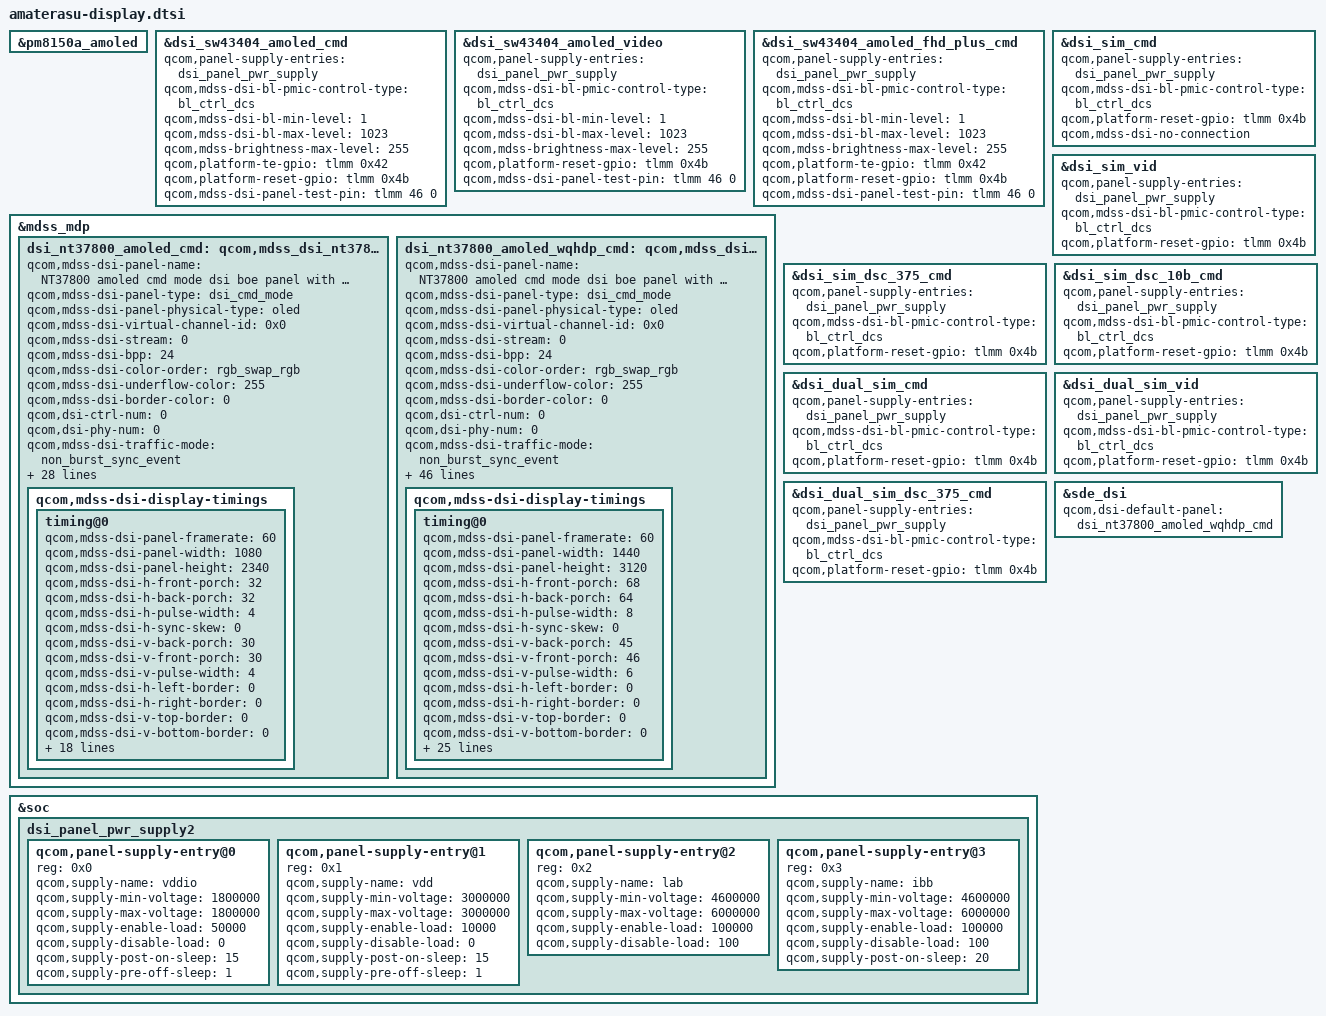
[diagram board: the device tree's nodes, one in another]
/*
 * FCNT arrows 5G (F-51A) - Display: NT37800 AMOLED panels (WQHD+/FHD+, DSC cmd mode), panel supplies and DSI.
 *
 * Reconstructed from the FCNT stock dtbo (kona FFRD REV7 SKU3); FFRD is
 * derived from the CLO kona QRD board files.
 */

&pm8150a_amoled {
	status = "ok";
};

&dsi_sw43404_amoled_cmd {
	qcom,panel-supply-entries = <&dsi_panel_pwr_supply>;
	qcom,mdss-dsi-bl-pmic-control-type = "bl_ctrl_dcs";
	qcom,mdss-dsi-bl-min-level = <1>;
	qcom,mdss-dsi-bl-max-level = <1023>;
	qcom,mdss-brightness-max-level = <255>;
	qcom,platform-te-gpio = <&tlmm 0x42 0x0>;
	qcom,platform-reset-gpio = <&tlmm 0x4b 0x0>;
	qcom,mdss-dsi-panel-test-pin = <&tlmm 46 0>;
};

&dsi_sw43404_amoled_video {
	qcom,panel-supply-entries = <&dsi_panel_pwr_supply>;
	qcom,mdss-dsi-bl-pmic-control-type = "bl_ctrl_dcs";
	qcom,mdss-dsi-bl-min-level = <1>;
	qcom,mdss-dsi-bl-max-level = <1023>;
	qcom,mdss-brightness-max-level = <255>;
	qcom,platform-reset-gpio = <&tlmm 0x4b 0x0>;
	qcom,mdss-dsi-panel-test-pin = <&tlmm 46 0>;
};

&dsi_sw43404_amoled_fhd_plus_cmd {
	qcom,panel-supply-entries = <&dsi_panel_pwr_supply>;
	qcom,mdss-dsi-bl-pmic-control-type = "bl_ctrl_dcs";
	qcom,mdss-dsi-bl-min-level = <1>;
	qcom,mdss-dsi-bl-max-level = <1023>;
	qcom,mdss-brightness-max-level = <255>;
	qcom,platform-te-gpio = <&tlmm 0x42 0x0>;
	qcom,platform-reset-gpio = <&tlmm 0x4b 0x0>;
	qcom,mdss-dsi-panel-test-pin = <&tlmm 46 0>;
};

&mdss_mdp {
	dsi_nt37800_amoled_cmd: qcom,mdss_dsi_nt37800_amoled_fhdp_cmd {
		qcom,mdss-dsi-panel-name = "NT37800 amoled cmd mode dsi boe panel with DSC";
		qcom,mdss-dsi-panel-type = "dsi_cmd_mode";
		qcom,mdss-dsi-panel-physical-type = "oled";
		qcom,mdss-dsi-virtual-channel-id = <0x0>;
		qcom,mdss-dsi-stream = <0>;
		qcom,mdss-dsi-bpp = <24>;
		qcom,mdss-dsi-color-order = "rgb_swap_rgb";
		qcom,mdss-dsi-underflow-color = <255>;
		qcom,mdss-dsi-border-color = <0>;
		qcom,dsi-ctrl-num = <0>;
		qcom,dsi-phy-num = <0>;
		qcom,mdss-dsi-traffic-mode = "non_burst_sync_event";
		qcom,mdss-dsi-lane-map = "lane_map_0123";
		qcom,mdss-dsi-bllp-eof-power-mode;
		qcom,mdss-dsi-bllp-power-mode;
		qcom,mdss-dsi-lane-0-state;
		qcom,mdss-dsi-lane-1-state;
		qcom,mdss-dsi-lane-2-state;
		qcom,mdss-dsi-lane-3-state;
		qcom,mdss-dsi-dma-trigger = "trigger_sw";
		qcom,mdss-dsi-mdp-trigger = "none";
		qcom,mdss-dsi-reset-sequence = <1 15 0 1 1 10>;
		qcom,mdss-dsi-te-pin-select = <1>;
		qcom,mdss-dsi-wr-mem-start = <44>;
		qcom,mdss-dsi-wr-mem-continue = <60>;
		qcom,mdss-dsi-te-dcs-command = <0x1>;
		qcom,mdss-dsi-te-check-enable;
		qcom,mdss-dsi-te-using-te-pin;
		qcom,mdss-dsi-lp11-init;
		qcom,dsi-select-clocks = "mux_byte_clk0", "mux_pixel_clk0";
		qcom,panel-supply-entries = <&dsi_panel_pwr_supply2>;
		qcom,mdss-dsi-bl-pmic-control-type = "bl_ctrl_dcs";
		qcom,mdss-dsi-bl-min-level = <1>;
		qcom,mdss-dsi-bl-max-level = <4095>;
		qcom,mdss-brightness-max-level = <255>;
		qcom,platform-te-gpio = <&tlmm 0x42 0x0>;
		qcom,platform-reset-gpio = <&tlmm 0x4b 0x0>;

		qcom,mdss-dsi-display-timings {
			timing@0 {
				qcom,mdss-dsi-panel-framerate = <60>;
				qcom,mdss-dsi-panel-width = <1080>;
				qcom,mdss-dsi-panel-height = <2340>;
				qcom,mdss-dsi-h-front-porch = <32>;
				qcom,mdss-dsi-h-back-porch = <32>;
				qcom,mdss-dsi-h-pulse-width = <4>;
				qcom,mdss-dsi-h-sync-skew = <0>;
				qcom,mdss-dsi-v-back-porch = <30>;
				qcom,mdss-dsi-v-front-porch = <30>;
				qcom,mdss-dsi-v-pulse-width = <4>;
				qcom,mdss-dsi-h-left-border = <0>;
				qcom,mdss-dsi-h-right-border = <0>;
				qcom,mdss-dsi-v-top-border = <0>;
				qcom,mdss-dsi-v-bottom-border = <0>;
				qcom,mdss-dsi-panel-jitter = <4 1>;
				qcom,mdss-dsi-on-command = <0x39010000 0x6f0 0x55aa5208 0x390100 0x25 0xb3000100 0x32003200 0x64006400 0xc800c801 0x2c012c01 0x90019003 0x48034804 0xb004b006 0x4006400f 0xff390100 0x1e 0xb4999999 0x88887755 0x3300000d 0xd0d0d0d 0xdc6c650 0x50dada8c 0x8cf4f438 0x38383901 0x0 0x26f0139 0x1000000 0x2b500 0x39010000 0x26f 0x5390100 0x2 0xb57f3901 0x0 0x6f055aa 0x52080039 0x1000000 0x26f06 0x39010000 0x4b5 0x48230039 0x1000000 0x26f0b 0x39010000 0x4b5 0x48230039 0x1000000 0x16b200 0x60202000 0x8080000 0x20000000 0x20000000 0x0 0x39010000 0x26f 0x24390100 0x9 0xb302a006 0x750f870f 0xff390100 0x2 0x6f243901 0x0 0xbb403b4 0x3b403b4 0x3b403b4 0x39010000 0x26f 0xb390100 0x2 0xb2003901 0x0 0x3b91000 0x39010000 0x9ba 0x1ac0010 0x208001 0x39010000 0x26f 0x8390100 0x9 0xba01ac00 0x10002000 0x20390100 0x2 0x6f103901 0x0 0xfba01ac 0x100020 0x1ac0010 0x200000 0x39010000 0x26f 0x1e390100 0x5 0xba110101 0x1390100 0x9 0xbb01ac00 0x10002000 0x41390100 0x4 0xbde100e1 0x39010000 0x6be 0xe10111f 0x1f390100 0x3 0xc0767339 0x1000000 0x26f02 0x39010000 0x2c0 0x390100 0x2 0x6f0e3901 0x0 0x2ba3839 0x1000000 0x26f03 0x39010000 0x4c0 0x39 0x1000000 0x3c100 0x62390100 0x2 0xc2013901 0x0 0x7c30000 0x0 0x39010000 0x3c5 0x5003901 0x0 0x5c63f00 0x3901 0x0 0x2c80d39 0x1000000 0x2c984 0x39010000 0x2ca 0x33390100 0x2 0xcb883901 0x0 0x2df0039 0x1000000 0x26f22 0x39010000 0x3df 0x803901 0x0 0x6f055aa 0x52080139 0x1000000 0x3b000 0x390100 0x3 0xb3050139 0x1000000 0x7b714 0x14141414 0x14390100 0x3 0xb1000039 0x1000000 0x3b405 0x1390100 0x5 0xb83d3d3d 0x3d390100 0x7 0xb500d700 0xd700d739 0x1000000 0x7b600 0x78007800 0x78390100 0x9 0xc200d700 0x7800d700 0x78390100 0x9 0xb91e1a1e 0x1a1e1a1e 0x1a390100 0x5 0xba101410 0x14390100 0x3 0xbb1e1e39 0x1000000 0x3cd05 0x82390100 0x2 0xc7013901 0x0 0x26f0139 0x1000000 0x4ce28 0x1003901 0x0 0x5cf0d02 0x13073901 0x0 0x2bc1139 0x1000000 0x11bd96 0x690000 0x960069bb 0x4444bbee 0x1111ee39 0x1000000 0x2c102 0x39010000 0x9c2 0x19009100 0x19009100 0x39010000 0x3c0 0x3901 0x0 0x6f055aa 0x52080339 0x1000000 0x6b000 0x2 0x39010000 0xbb2 0xc 0x1000000 0xc013901 0x0 0xbb30000 0xd2100 0xd21 0x39010000 0x7b4 0x0 0x3901 0x0 0x16b60300 0x0 0xd00 0x0 0xd000000 0x39 0x1000000 0x8bb22 0x181600 0x18163901 0x0 0x8bc2210 0x1e4c001e 0x4c390100 0x8 0xbd110009 0x60000960 0x39010000 0x4c3 0xa39 0x1000000 0x6f055 0xaa520805 0x39010000 0x4b0 0x7230039 0x1000000 0x3b388 0x80390100 0x3 0xb5040539 0x1000000 0x3b686 0x85390100 0x5 0xb7040000 0x5390100 0x5 0xb8040000 0x5390100 0x5 0xb9040000 0x5390100 0x3 0xc7070139 0x1000000 0x2ca33 0x39010000 0x4cb 0x33333339 0x1000000 0x2d822 0x39010000 0x2d9 0x1390100 0x4 0xd0000020 0x39010000 0x4d1 0x31039 0x1000000 0x4d200 0x8103901 0x0 0x5e00200 0x3901 0x0 0x5e10200 0x33901 0x0 0x5e20099 0x28003901 0x0 0x3ec0111 0x39010000 0x6f0 0x55aa5208 0x6390100 0x6 0xb0041011 0x34003901 0x0 0x6b1000e 0xe0f0f39 0x1000000 0x6b20c 0xc0d0d34 0x39010000 0x6b3 0x34343434 0x34390100 0x5 0xb4141415 0x15390100 0x6 0xb6041011 0x34003901 0x0 0x6b7000e 0xe0f0f39 0x1000000 0x6b80c 0xc0d0d34 0x39010000 0x6b9 0x34343434 0x34390100 0x5 0xba141415 0x15390100 0x2 0xd0013901 0x0 0x6f055aa 0x52080739 0x1000000 0x7b0a4 0x40706000 0x390100 0x3 0xb7809039 0x1000000 0x26f43 0x39010000 0x4b7 0x80708039 0x1000000 0x26f46 0x39010000 0x4b7 0x80708039 0x1000000 0x18b10c 0x1c001c0c 0x0 0x0 0x0 0x0 0x3901 0x0 0xb5b22222 0x22222222 0x22222222 0x22222222 0x22222222 0x0 0x0 0x222222 0x22222222 0x22222222 0x22222222 0x22222200 0x0 0x0 0x3a3a3a3a 0x3a3a3a3a 0x3a050505 0x5050505 0x5053a3a 0x3a3a3a3a 0x3a3a3a05 0x5050505 0x5050505 0x0 0x0 0x0 0x0 0x3a3a 0x3a3a3a3a 0x3a3a3a05 0x5050505 0x5050505 0x3a3a3a3a 0x3a3a3a3a 0x3a050505 0x5050505 0x5050000 0x0 0x0 0x0 0x0 0x0 0x0 0x0 0x0 0x3901 0x0 0x5bb30000 0x0 0x0 0x0 0x0 0x0 0x0 0x0 0x0 0x0 0x0 0x0 0x0 0x0 0x0 0x0 0x0 0x0 0x0 0x0 0x0 0x0 0x0 0x39010000 0x1bb4 0xc0000000 0x0 0x0 0x8068 0x80806080 0x80608080 0xa0803901 0x0 0x49b50000 0x0 0x0 0x0 0x0 0x0 0x4000000 0x0 0x0 0x0 0x0 0x0 0x0 0x0 0x0 0x0 0x0 0x0 0x3901 0x0 0x25b60000 0x0 0x0 0x0 0x0 0x0 0xe000 0xe0000000 0xe000e000 0x3901 0x0 0x58b80000 0x0 0x0 0x0 0x0 0x20200 0x0 0x0 0x0 0x0 0x0 0x0 0x0 0x0 0x0 0x0 0x0 0x0 0x0 0x0 0x0 0x0 0x390100 0xc1 0xb9000000 0x0 0x0 0x0 0x0 0x0 0x0 0x0 0x0 0x0 0x0 0x0 0x0 0x0 0x0 0x0 0x0 0x0 0x0 0x0 0x0 0x0 0x0 0x0 0x0 0x0 0x0 0x0 0x0 0x0 0x0 0x0 0x0 0x0 0x0 0x0 0x0 0x0 0x0 0x0 0x0 0x0 0x0 0x0 0x0 0x0 0x0 0x0 0x390100 0x20 0xba000000 0x0 0x0 0x0 0x0 0x0 0x0 0x0 0x39010000 0x88bb 0x0 0x0 0x0 0x0 0x0 0x0 0x0 0x0 0x0 0x0 0x0 0x0 0x0 0x0 0x0 0x0 0x0 0x0 0x0 0x0 0x0 0x0 0x0 0x0 0x0 0x0 0x0 0x0 0x0 0x0 0x0 0x0 0x0 0x39 0x1000000 0x14bc00 0x0 0x0 0x0 0x0 0x3901 0x0 0xdbd0000 0x0 0x0 0x3901 0x0 0x6f055aa 0x52080739 0x1000000 0x2c011 0x39010000 0x27c1 0x603c0349 0xf7d80510 0x3ffd9664 0x3ffb843c 0x7163 0xa41d0020 0x7e1d 0x0 0x1f1df7ff 0xffff3901 0x0 0x27c2483c 0x441f90a 0x2d93ffb 0x69c23ffd 0x9ea60000 0x7e398161 0x1e00 0x1f7ff7ff 0xfff7ffff 0xf7ffffff 0x39010000 0x27c3 0x6c000441 0x6f602d9 0x3ff8c68c 0x38e8 0x0 0x618000 0xa4901f05 0x90000690 0x1f23f7ff 0xffff3901 0x0 0x27c44400 0x3490828 0x5103ffc 0xa9dc0003 0x56240000 0x1d 0x90200690 0x7e23f7ff 0xfff7ffff 0xf7ffffff 0x39010000 0x27c5 0x623c0349 0xf7d80510 0xec88 0x654d4 0x7fff37c2 0x6c1d93b9 0x6941723 0x94180694 0x3723f7ff 0xffff3901 0x0 0x27c64a3c 0x441f802 0x3c10006 0xf6be0000 0xf7c27fff 0x1826fd61 0x8418a494 0x3705f7ff 0xfff7ffff 0xf7ffffff 0x39010000 0x27c7 0x660004c9 0x87a03c1 0x3df08 0x3ffc20f8 0x0 0x418 0x1e04377f 0x4180004 0x371df7ff 0xffff3901 0x0 0x27c84600 0x3490828 0x5100000 0x3ff8 0x858c0000 0x1d 0x3b90004 0x171df7ff 0xfff7ffff 0xf7ffffff 0x39010000 0x27c9 0x0 0x0 0x0 0x0 0x0 0xf7ff 0xfff7ffff 0xf7fffff7 0xfffff7ff 0xffff3901 0x0 0x27ca0000 0x0 0x0 0x0 0x0 0x0 0xf7fffff7 0xfffff7ff 0xfff7ffff 0xf7ffffff 0x39010000 0x27cb 0x0 0x0 0x0 0x0 0x0 0xf7ff 0xfff7ffff 0xf7fffff7 0xfffff7ff 0xffff3901 0x0 0x27cc0000 0x0 0x0 0x0 0x0 0x0 0xf7fffff7 0xfffff7ff 0xfff7ffff 0xf7ffffff 0x39010000 0x27cd 0x20000000 0x0 0x0 0x0 0x0 0x179 0x19c1a 0x19d0001 0xa015f7ff 0xffff3901 0x0 0x27ce0000 0x0 0x0 0x0 0x0 0x0 0x19d1601 0xe74ff7ff 0xfff7ffff 0xf7ffffff 0x39010000 0x27cf 0x20000000 0x0 0x0 0x0 0x0 0x250 0x16029a4f 0x2970002 0x9a15f7ff 0xffff3901 0x0 0x27d00000 0x0 0x0 0x0 0x0 0x0 0x29b0002 0xbe1a9000 0x6f7ffff 0xf7ffffff 0x39010000 0x5ff 0xaa55a581 0x39010000 0x26f 0x2c390100 0x2 0xfa003901 0x0 0x6f055aa 0x52000039 0x1000000 0x23500 0x39010000 0x53b 0x100004 0x39010000 0x253 0x20390100 0x5 0x5100ff0f 0xff390100 0x5 0x510fff0f 0xff390100 0x5 0x2a000004 0x37390100 0x5 0x2b000009 0x23390100 0x13 0x93892800 0x14020002 0xe01e800 0x7050e05 0x1610f039 0x1000000 0x29001 0x39010000 0x203 0x11390100 0x2 0x2c003901 0x0 0x22f0139 0x1000000 0x6f055 0xaa520800 0x39010000 0x26f 0xe390100 0x2 0xba383901 0x0 0x26f0339 0x1000000 0x4c080 0x3901 0x7800 0x2110005 0x1000000 0x22900>;
				qcom,mdss-dsi-off-command = [05 01 00 00 23 00 02 28 00 05 01 00 00 78 00 02 10 00];
				qcom,mdss-dsi-on-command-state = "dsi_lp_mode";
				qcom,mdss-dsi-off-command-state = "dsi_hs_mode";
				qcom,compression-mode = "dsc";
				qcom,mdss-dsc-slice-height = <20>;
				qcom,mdss-dsc-slice-width = <540>;
				qcom,mdss-dsc-slice-per-pkt = <2>;
				qcom,mdss-dsc-bit-per-component = <8>;
				qcom,mdss-dsc-bit-per-pixel = <8>;
				qcom,mdss-dsc-block-prediction-enable;
				qcom,mdss-dsi-panel-phy-timings = [00 0f 03 03 1e 1d 04 04 02 02 04 00 0f 13];
				qcom,display-topology = <2 2 1>;
				qcom,default-topology-index = <0>;
			};
		};
	};

	dsi_nt37800_amoled_wqhdp_cmd: qcom,mdss_dsi_nt37800_amoled_wqhdp_cmd {
		qcom,mdss-dsi-panel-name = "NT37800 amoled cmd mode dsi boe panel with DSC";
		qcom,mdss-dsi-panel-type = "dsi_cmd_mode";
		qcom,mdss-dsi-panel-physical-type = "oled";
		qcom,mdss-dsi-virtual-channel-id = <0x0>;
		qcom,mdss-dsi-stream = <0>;
		qcom,mdss-dsi-bpp = <24>;
		qcom,mdss-dsi-color-order = "rgb_swap_rgb";
		qcom,mdss-dsi-underflow-color = <255>;
		qcom,mdss-dsi-border-color = <0>;
		qcom,dsi-ctrl-num = <0>;
		qcom,dsi-phy-num = <0>;
		qcom,mdss-dsi-traffic-mode = "non_burst_sync_event";
		qcom,mdss-dsi-lane-map = "lane_map_0123";
		qcom,mdss-dsi-bllp-eof-power-mode;
		qcom,mdss-dsi-bllp-power-mode;
		qcom,mdss-dsi-lane-0-state;
		qcom,mdss-dsi-lane-1-state;
		qcom,mdss-dsi-lane-2-state;
		qcom,mdss-dsi-lane-3-state;
		qcom,mdss-dsi-dma-trigger = "trigger_sw";
		qcom,mdss-dsi-mdp-trigger = "none";
		qcom,mdss-dsi-reset-sequence = <1 15 0 1 1 10>;
		qcom,mdss-dsi-te-pin-select = <1>;
		qcom,mdss-dsi-wr-mem-start = <44>;
		qcom,mdss-dsi-wr-mem-continue = <60>;
		qcom,mdss-dsi-te-dcs-command = <0x1>;
		qcom,mdss-dsi-te-check-enable;
		qcom,mdss-dsi-te-using-te-pin;
		qcom,mdss-dsi-lp11-init;
		qcom,mdss-pan-physical-width-dimension = <71>;
		qcom,mdss-pan-physical-height-dimension = <154>;
		qcom,mdss-dsi-panel-hdr-enabled;
		qcom,mdss-dsi-panel-hdr-color-primaries = <14950 15750 33950 16000 13000 35200 7000 2600>;
		qcom,mdss-dsi-panel-peak-brightness = <4200000>;
		qcom,mdss-dsi-panel-blackness-level = <1>;
		qcom,esd-check-enabled;
		qcom,mdss-dsi-panel-status-check-mode = "reg_read";
		qcom,mdss-dsi-panel-status-command = <0x6010001 0x10a>;
		qcom,mdss-dsi-panel-status-command-state = "dsi_lp_mode";
		qcom,mdss-dsi-panel-status-value = <156>;
		qcom,mdss-dsi-panel-status-read-length = <1>;
		qcom,dsi-select-clocks = "mux_byte_clk0", "mux_pixel_clk0";
		qcom,panel-supply-entries = <&dsi_panel_pwr_supply2>;
		qcom,mdss-dsi-bl-pmic-control-type = "bl_ctrl_dcs";
		qcom,mdss-dsi-bl-min-level = <1>;
		qcom,mdss-dsi-bl-max-level = <2874>;
		qcom,mdss-dsi-bl-super-clear-level = <4095>;
		qcom,mdss-brightness-max-level = <255>;
		qcom,platform-te-gpio = <&tlmm 0x42 0x0>;
		qcom,platform-reset-gpio = <&tlmm 0x4b 0x0>;
		qcom,mdss-dsi-panel-test-pin = <&tlmm 46 0>;

		qcom,mdss-dsi-display-timings {
			timing@0 {
				qcom,mdss-dsi-panel-framerate = <60>;
				qcom,mdss-dsi-panel-width = <1440>;
				qcom,mdss-dsi-panel-height = <3120>;
				qcom,mdss-dsi-h-front-porch = <68>;
				qcom,mdss-dsi-h-back-porch = <64>;
				qcom,mdss-dsi-h-pulse-width = <8>;
				qcom,mdss-dsi-h-sync-skew = <0>;
				qcom,mdss-dsi-v-back-porch = <45>;
				qcom,mdss-dsi-v-front-porch = <46>;
				qcom,mdss-dsi-v-pulse-width = <6>;
				qcom,mdss-dsi-h-left-border = <0>;
				qcom,mdss-dsi-h-right-border = <0>;
				qcom,mdss-dsi-v-top-border = <0>;
				qcom,mdss-dsi-v-bottom-border = <0>;
				qcom,mdss-dsi-panel-jitter = <4 1>;
				qcom,mdss-dsi-on-command = [39 01 00 00 00 00 06 f0 55 aa 52 08 00 39 01 00 00 00 00 03 b5 84 00 39 01 00 00 00 00 02 6f 05 39 01 00 00 00 00 05 b5 7f 48 16 51 39 01 00 00 00 00 08 b7 aa aa aa aa 86 42 10 39 01 00 00 00 00 02 6f 0b 39 01 00 00 00 00 04 b5 48 29 00 39 01 00 00 00 00 06 f0 55 aa 52 08 00 39 01 00 00 00 00 04 c0 76 73 00 39 01 00 00 00 00 06 f0 55 aa 52 08 01 39 01 00 00 00 00 02 6f 05 39 01 00 00 00 00 03 d2 40 07 39 01 00 00 00 00 05 ff aa 55 a5 81 39 01 00 00 00 00 02 6f 0d 39 01 00 00 00 00 02 f3 cb 39 01 00 00 00 00 02 6f 2c 39 01 00 00 00 00 02 fa 00 39 01 00 00 00 00 05 ff aa 55 a5 80 39 01 00 00 00 00 02 6f 0a 39 01 00 00 00 00 02 fc 02 39 01 00 00 00 00 05 ff aa 55 a5 00 39 01 00 00 00 00 06 f0 55 aa 52 00 00 39 01 00 00 00 00 02 35 00 39 01 00 00 00 00 05 3b 00 08 00 08 39 01 00 00 00 00 02 53 20 39 01 00 00 00 00 05 51 00 00 0f ff 39 01 00 00 00 00 05 2a 00 00 05 9f 39 01 00 00 00 00 05 2b 00 00 0c 2f 39 01 00 00 00 00 13 93 89 28 00 14 02 00 02 68 02 2e 00 0a 05 0e 03 d1 10 f0 39 01 00 00 00 00 02 90 01 39 01 00 00 00 00 02 03 11 39 01 00 00 00 00 02 2c 00 39 01 00 00 78 00 02 11 00 05 01 00 00 00 00 02 29 00];
				qcom,mdss-dsi-off-command = [05 01 00 00 23 00 02 28 00 05 01 00 00 78 00 02 10 00];
				qcom,mdss-dsi-on-command-state = "dsi_lp_mode";
				qcom,mdss-dsi-off-command-state = "dsi_hs_mode";
				qcom,mdss-dsi-lp1-command = [05 01 00 00 00 00 02 39 00 39 01 00 00 00 00 02 65 01 39 01 00 00 00 00 02 2c 00];
				qcom,mdss-dsi-lp1-command-state = "dsi_lp_mode";
				qcom,mdss-dsi-nolp-command = [05 01 00 00 00 00 02 38 00 39 01 00 00 00 00 02 65 00 39 01 00 00 00 00 02 2c 00];
				qcom,mdss-dsi-nolp-command-state = "dsi_lp_mode";
				qcom,compression-mode = "dsc";
				qcom,mdss-dsc-slice-height = <20>;
				qcom,mdss-dsc-slice-width = <720>;
				qcom,mdss-dsc-slice-per-pkt = <2>;
				qcom,mdss-dsc-bit-per-component = <8>;
				qcom,mdss-dsc-bit-per-pixel = <8>;
				qcom,mdss-dsc-block-prediction-enable;
				qcom,mdss-dsi-panel-phy-timings = [00 19 06 06 21 20 07 06 04 02 04 00 15 16];
				qcom,display-topology = <2 2 1>;
				qcom,default-topology-index = <0>;
				qcom,mdss-dsi-panel-clockrate = <0x2acbcf80>;
			};
		};
	};
};

&dsi_sim_cmd {
	qcom,panel-supply-entries = <&dsi_panel_pwr_supply>;
	qcom,mdss-dsi-bl-pmic-control-type = "bl_ctrl_dcs";
	qcom,platform-reset-gpio = <&tlmm 0x4b 0x0>;
	qcom,mdss-dsi-no-connection;
};

&dsi_sim_vid {
	qcom,panel-supply-entries = <&dsi_panel_pwr_supply>;
	qcom,mdss-dsi-bl-pmic-control-type = "bl_ctrl_dcs";
	qcom,platform-reset-gpio = <&tlmm 0x4b 0x0>;
};

&dsi_sim_dsc_375_cmd {
	qcom,panel-supply-entries = <&dsi_panel_pwr_supply>;
	qcom,mdss-dsi-bl-pmic-control-type = "bl_ctrl_dcs";
	qcom,platform-reset-gpio = <&tlmm 0x4b 0x0>;
};

&dsi_sim_dsc_10b_cmd {
	qcom,panel-supply-entries = <&dsi_panel_pwr_supply>;
	qcom,mdss-dsi-bl-pmic-control-type = "bl_ctrl_dcs";
	qcom,platform-reset-gpio = <&tlmm 0x4b 0x0>;
};

&dsi_dual_sim_cmd {
	qcom,panel-supply-entries = <&dsi_panel_pwr_supply>;
	qcom,mdss-dsi-bl-pmic-control-type = "bl_ctrl_dcs";
	qcom,platform-reset-gpio = <&tlmm 0x4b 0x0>;
};

&dsi_dual_sim_vid {
	qcom,panel-supply-entries = <&dsi_panel_pwr_supply>;
	qcom,mdss-dsi-bl-pmic-control-type = "bl_ctrl_dcs";
	qcom,platform-reset-gpio = <&tlmm 0x4b 0x0>;
};

&dsi_dual_sim_dsc_375_cmd {
	qcom,panel-supply-entries = <&dsi_panel_pwr_supply>;
	qcom,mdss-dsi-bl-pmic-control-type = "bl_ctrl_dcs";
	qcom,platform-reset-gpio = <&tlmm 0x4b 0x0>;
};

&soc {
	dsi_panel_pwr_supply2: dsi_panel_pwr_supply2 {
		#address-cells = <0x1>;
		#size-cells = <0x0>;

		qcom,panel-supply-entry@0 {
			reg = <0x0>;
			qcom,supply-name = "vddio";
			qcom,supply-min-voltage = <1800000>;
			qcom,supply-max-voltage = <1800000>;
			qcom,supply-enable-load = <50000>;
			qcom,supply-disable-load = <0>;
			qcom,supply-post-on-sleep = <15>;
			qcom,supply-pre-off-sleep = <1>;
		};

		qcom,panel-supply-entry@1 {
			reg = <0x1>;
			qcom,supply-name = "vdd";
			qcom,supply-min-voltage = <3000000>;
			qcom,supply-max-voltage = <3000000>;
			qcom,supply-enable-load = <10000>;
			qcom,supply-disable-load = <0>;
			qcom,supply-post-on-sleep = <15>;
			qcom,supply-pre-off-sleep = <1>;
		};

		qcom,panel-supply-entry@2 {
			reg = <0x2>;
			qcom,supply-name = "lab";
			qcom,supply-min-voltage = <4600000>;
			qcom,supply-max-voltage = <6000000>;
			qcom,supply-enable-load = <100000>;
			qcom,supply-disable-load = <100>;
		};

		qcom,panel-supply-entry@3 {
			reg = <0x3>;
			qcom,supply-name = "ibb";
			qcom,supply-min-voltage = <4600000>;
			qcom,supply-max-voltage = <6000000>;
			qcom,supply-enable-load = <100000>;
			qcom,supply-disable-load = <100>;
			qcom,supply-post-on-sleep = <20>;
		};
	};
};

&sde_dsi {
	qcom,dsi-default-panel = <&dsi_nt37800_amoled_wqhdp_cmd>;
};
